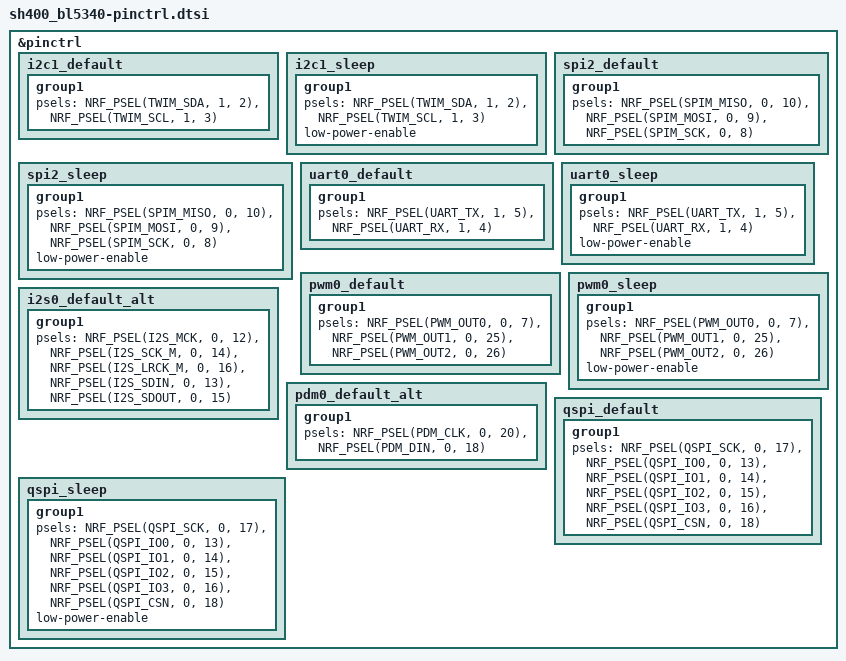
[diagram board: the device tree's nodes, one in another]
/*
 * Copyright (c) 2022 Nordic Semiconductor
 * SPDX-License-Identifier: Apache-2.0
 */

&pinctrl {
	i2c1_default: i2c1_default {
		group1 {
			psels = <NRF_PSEL(TWIM_SDA, 1, 2)>,
				<NRF_PSEL(TWIM_SCL, 1, 3)>;
		};
	};

	i2c1_sleep: i2c1_sleep {
		group1 {
			psels = <NRF_PSEL(TWIM_SDA, 1, 2)>,
				<NRF_PSEL(TWIM_SCL, 1, 3)>;
			low-power-enable;
		};
	};

	spi2_default: spi2_default {
		group1 {
			psels = <NRF_PSEL(SPIM_MISO, 0, 10)>,
				<NRF_PSEL(SPIM_MOSI, 0, 9)>,
				<NRF_PSEL(SPIM_SCK, 0, 8)>;
		};
	};

	spi2_sleep: spi2_sleep {
		group1 {
			psels = <NRF_PSEL(SPIM_MISO, 0, 10)>,
				<NRF_PSEL(SPIM_MOSI, 0, 9)>,
				<NRF_PSEL(SPIM_SCK, 0, 8)>;
			low-power-enable;
		};
	};

	uart0_default: uart0_default {
		group1 {
			psels = <NRF_PSEL(UART_TX, 1, 5)>,
				<NRF_PSEL(UART_RX, 1, 4)>;
		};
	};

	uart0_sleep: uart0_sleep {
		group1 {
			psels = <NRF_PSEL(UART_TX, 1, 5)>,
				<NRF_PSEL(UART_RX, 1, 4)>;
			low-power-enable;
		};
	};

	pwm0_default: pwm0_default {
        group1 {
            psels = <NRF_PSEL(PWM_OUT0, 0, 7)>,   /* Red */
                    <NRF_PSEL(PWM_OUT1, 0, 25)>,  /* Green */
                    <NRF_PSEL(PWM_OUT2, 0, 26)>;  /* Blue */
        };
    };

    pwm0_sleep: pwm0_sleep {
        group1 {
            psels = <NRF_PSEL(PWM_OUT0, 0, 7)>,
                    <NRF_PSEL(PWM_OUT1, 0, 25)>,
                    <NRF_PSEL(PWM_OUT2, 0, 26)>;
            low-power-enable;
        };
    };

	i2s0_default_alt: i2s0_default_alt {
		group1 {
			psels = <NRF_PSEL(I2S_MCK, 0, 12)>,    /* P0.12 - I2S_MCLK */
					<NRF_PSEL(I2S_SCK_M, 0, 14)>,    /* P0.14 - I2S_BCLK */
					<NRF_PSEL(I2S_LRCK_M, 0, 16)>,   /* P0.16 - I2S_FSYNC */
					<NRF_PSEL(I2S_SDIN, 0, 13)>,   /* P0.13 - I2S_DIN */
					<NRF_PSEL(I2S_SDOUT, 0, 15)>;  /* P0.15 - I2S_DOUT */
		};
	};

	pdm0_default_alt: pdm0_default_alt {
		group1 {
			psels = <NRF_PSEL(PDM_CLK, 0, 20)>,
				<NRF_PSEL(PDM_DIN, 0, 18)>;
		};
	};

	qspi_default: qspi_default {
		group1 {
			psels = <NRF_PSEL(QSPI_SCK, 0, 17)>,
				<NRF_PSEL(QSPI_IO0, 0, 13)>,
				<NRF_PSEL(QSPI_IO1, 0, 14)>,
				<NRF_PSEL(QSPI_IO2, 0, 15)>,
				<NRF_PSEL(QSPI_IO3, 0, 16)>,
				<NRF_PSEL(QSPI_CSN, 0, 18)>;
		};
	};

	qspi_sleep: qspi_sleep {
		group1 {
			psels = <NRF_PSEL(QSPI_SCK, 0, 17)>,
				<NRF_PSEL(QSPI_IO0, 0, 13)>,
				<NRF_PSEL(QSPI_IO1, 0, 14)>,
				<NRF_PSEL(QSPI_IO2, 0, 15)>,
				<NRF_PSEL(QSPI_IO3, 0, 16)>,
				<NRF_PSEL(QSPI_CSN, 0, 18)>;
			low-power-enable;
		};
	};

};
